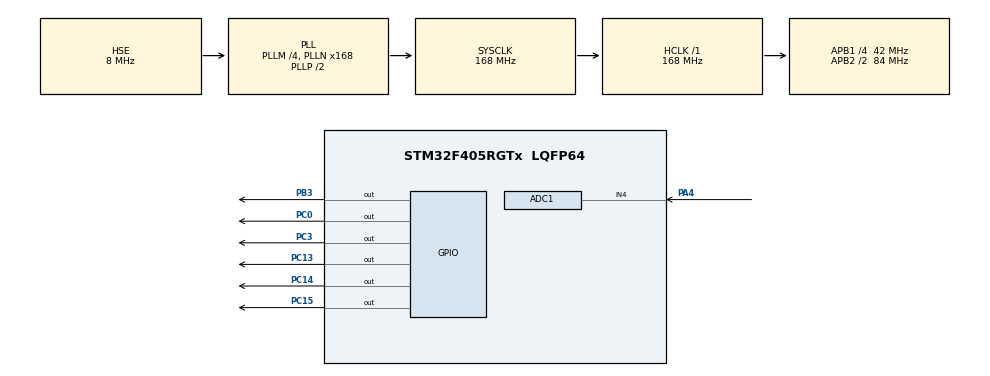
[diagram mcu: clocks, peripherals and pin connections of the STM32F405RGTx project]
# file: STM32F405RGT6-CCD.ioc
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ADC1.Channel-2\#ChannelRegularConversion=ADC_CHANNEL_4
ADC1.NbrOfConversionFlag=1
ADC1.Rank-2\#ChannelRegularConversion=1
ADC1.SamplingTime-2\#ChannelRegularConversion=ADC_SAMPLETIME_3CYCLES
ADC1.master=1
Mcu.Family=STM32F4
Mcu.Name=STM32F405RGTx
Mcu.Package=LQFP64
NVIC.PriorityGroup=NVIC_PRIORITYGROUP_4
NVIC.TIM3_IRQn=true\:0\:0\:false\:false\:true\:true\:true
PA13.Mode=Serial_Wire
PA13.Signal=SYS_JTMS-SWDIO
PA14.Mode=Serial_Wire
PA14.Signal=SYS_JTCK-SWCLK
PA4.Signal=ADCx_IN4
PB3.Signal=GPIO_Output
PC0.Signal=GPIO_Output
PC13-ANTI_TAMP.Signal=GPIO_Output
PC14-OSC32_IN.Signal=GPIO_Output
PC15-OSC32_OUT.Signal=GPIO_Output
PC3.Signal=GPIO_Output
PH0-OSC_IN.Mode=HSE-External-Oscillator
PH0-OSC_IN.Signal=RCC_OSC_IN
PH1-OSC_OUT.Mode=HSE-External-Oscillator
PH1-OSC_OUT.Signal=RCC_OSC_OUT
ProjectManager.HeapSize=0x200
ProjectManager.StackSize=0x400
ProjectManager.TargetToolchain=MDK-ARM V5.32
RCC.48MHZClocksFreq_Value=84000000
RCC.AHBFreq_Value=168000000
RCC.APB1CLKDivider=RCC_HCLK_DIV4
RCC.APB1Freq_Value=42000000
RCC.APB1TimFreq_Value=84000000
RCC.APB2CLKDivider=RCC_HCLK_DIV2
RCC.APB2Freq_Value=84000000
RCC.APB2TimFreq_Value=168000000
RCC.CortexFreq_Value=168000000
RCC.HCLKFreq_Value=168000000
RCC.HSE_VALUE=8000000
RCC.HSI_VALUE=16000000
RCC.LSE_VALUE=32768
RCC.PLLM=4
RCC.PLLN=168
RCC.PLLSourceVirtual=RCC_PLLSOURCE_HSE
RCC.SYSCLKFreq_VALUE=168000000
RCC.SYSCLKSource=RCC_SYSCLKSOURCE_PLLCLK
RCC.VCOOutputFreq_Value=336000000
SH.ADCx_IN4.0=ADC1_IN4,IN4
TIM3.AutoReloadPreload=TIM_AUTORELOAD_PRELOAD_ENABLE
TIM3.Period=8399
TIM3.Prescaler=49
VP_TIM3_VS_ClockSourceINT.Mode=Internal
board=custom

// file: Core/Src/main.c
/* USER CODE BEGIN Header */
/**
  ******************************************************************************
  * @file           : main.c
  * @brief          : Main program body
  ******************************************************************************
  * @attention
  *
  * <h2><center>&copy; Copyright (c) 2023 STMicroelectronics.
  * All rights reserved.</center></h2>
  *
  * This software component is licensed by ST under BSD 3-Clause license,
  * the "License"; You may not use this file except in compliance with the
  * License. You may obtain a copy of the License at:
  *                        opensource.org/licenses/BSD-3-Clause
  *
  ******************************************************************************
  */
/* USER CODE END Header */
#include "main.h"
#include "adc.h"
#include "tim.h"
#include "gpio.h"

/* USER CODE BEGIN Includes */
#include "sys.h"
/* USER CODE END Includes */

/* USER CODE BEGIN PM */
u8 CCD_Zhongzhi,CCD_Yuzhi;   //线性CCD  相关
/* USER CODE END PM */

void SystemClock_Config(void);

int main(void)
{

  /* MCU Configuration--------------------------------------------------------*/

  /* Reset of all peripherals, Initializes the Flash interface and the Systick. */
  HAL_Init();

  /* Configure the system clock */
  SystemClock_Config();

  /* USER CODE BEGIN SysInit */
  delay_init();
  /* USER CODE END SysInit */

  /* Initialize all configured peripherals */
  MX_GPIO_Init();
  MX_ADC1_Init();

  /* USER CODE BEGIN 2 */
  OLED_Init();
 MX_TIM3_Init();
  /* USER CODE END 2 */

  /* Infinite loop */
  while (1)
  {
     oled_show();
  }
}

void SystemClock_Config(void)
{
  RCC_OscInitTypeDef RCC_OscInitStruct = {0};
  RCC_ClkInitTypeDef RCC_ClkInitStruct = {0};

  /** Configure the main internal regulator output voltage
  */
  __HAL_RCC_PWR_CLK_ENABLE();
  __HAL_PWR_VOLTAGESCALING_CONFIG(PWR_REGULATOR_VOLTAGE_SCALE1);
  /** Initializes the RCC Oscillators according to the specified parameters
  * in the RCC_OscInitTypeDef structure.
  */
  RCC_OscInitStruct.OscillatorType = RCC_OSCILLATORTYPE_HSE;
  RCC_OscInitStruct.HSEState = RCC_HSE_ON;
  RCC_OscInitStruct.PLL.PLLState = RCC_PLL_ON;
  RCC_OscInitStruct.PLL.PLLSource = RCC_PLLSOURCE_HSE;
  RCC_OscInitStruct.PLL.PLLM = 4;
  RCC_OscInitStruct.PLL.PLLN = 168;
  RCC_OscInitStruct.PLL.PLLP = RCC_PLLP_DIV2;
  RCC_OscInitStruct.PLL.PLLQ = 4;
  if (HAL_RCC_OscConfig(&RCC_OscInitStruct) != HAL_OK)
  {
    Error_Handler();
  }
  /** Initializes the CPU, AHB and APB buses clocks
  */
  RCC_ClkInitStruct.ClockType = RCC_CLOCKTYPE_HCLK|RCC_CLOCKTYPE_SYSCLK
                              |RCC_CLOCKTYPE_PCLK1|RCC_CLOCKTYPE_PCLK2;
  RCC_ClkInitStruct.SYSCLKSource = RCC_SYSCLKSOURCE_PLLCLK;
  RCC_ClkInitStruct.AHBCLKDivider = RCC_SYSCLK_DIV1;
  RCC_ClkInitStruct.APB1CLKDivider = RCC_HCLK_DIV4;
  RCC_ClkInitStruct.APB2CLKDivider = RCC_HCLK_DIV2;

  if (HAL_RCC_ClockConfig(&RCC_ClkInitStruct, FLASH_LATENCY_5) != HAL_OK)
  {
    Error_Handler();
  }
}

void Error_Handler(void)
{
  __disable_irq();
  while (1)
  {
  }
}

/************************ (C) COPYRIGHT STMicroelectronics *****END OF FILE****/
